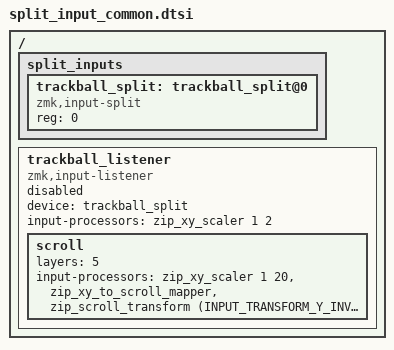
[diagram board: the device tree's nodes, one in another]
/* Common split input configuration - previously defined in pmw3610.dtsi */
/* Moved here to match known working config structure */

#include <dt-bindings/zmk/input_transform.h>
#include <input/processors.dtsi>

/ {
    split_inputs {
        #address-cells = <1>;
        #size-cells = <0>;

        trackball_split: trackball_split@0 {
            compatible = "zmk,input-split";
            reg = <0>;
        };
    };

    trackball_listener: trackball_listener {
        compatible = "zmk,input-listener";
        status = "disabled"; /* overridden on central */
        device = <&trackball_split>;

        input-processors = <&zip_xy_scaler 1 2>;

        scroll {
            layers = <5>; /* SCROLL layer */
            input-processors =
                <&zip_xy_scaler 1 20>,
                <&zip_xy_to_scroll_mapper>,
                <&zip_scroll_transform (INPUT_TRANSFORM_Y_INVERT)>;
        };
    };
};
